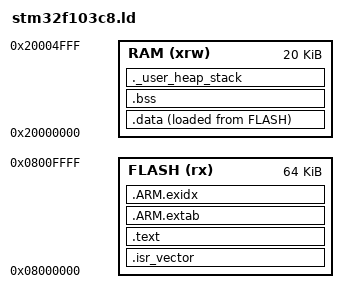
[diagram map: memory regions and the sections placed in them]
/* STM32F103C8: 64 KiB flash, 20 KiB SRAM. */
ENTRY(Reset_Handler)

MEMORY
{
    FLASH (rx)  : ORIGIN = 0x08000000, LENGTH = 64K
    RAM   (xrw) : ORIGIN = 0x20000000, LENGTH = 20K
}

_estack = ORIGIN(RAM) + LENGTH(RAM);
_Min_Heap_Size = 0x000;
_Min_Stack_Size = 0x600;

SECTIONS
{
    .isr_vector :
    {
        . = ALIGN(4);
        KEEP(*(.isr_vector))
        . = ALIGN(4);
    } > FLASH

    .text :
    {
        . = ALIGN(4);
        *(.text)
        *(.text*)
        *(.rodata)
        *(.rodata*)
        KEEP(*(.init))
        KEEP(*(.fini))
        . = ALIGN(4);
        _etext = .;
    } > FLASH

    .ARM.extab :
    {
        *(.ARM.extab* .gnu.linkonce.armextab.*)
    } > FLASH

    .ARM.exidx :
    {
        __exidx_start = .;
        *(.ARM.exidx*)
        __exidx_end = .;
    } > FLASH

    _sidata = LOADADDR(.data);

    .data :
    {
        . = ALIGN(4);
        _sdata = .;
        *(.data)
        *(.data*)
        . = ALIGN(4);
        _edata = .;
    } > RAM AT > FLASH

    .bss (NOLOAD) :
    {
        . = ALIGN(4);
        _sbss = .;
        *(.bss)
        *(.bss*)
        *(COMMON)
        . = ALIGN(4);
        _ebss = .;
    } > RAM

    ._user_heap_stack (NOLOAD) :
    {
        . = ALIGN(8);
        PROVIDE(end = .);
        PROVIDE(_end = .);
        . = . + _Min_Heap_Size;
        . = . + _Min_Stack_Size;
        . = ALIGN(8);
    } > RAM

    /DISCARD/ :
    {
        *(.note.GNU-stack)
        *(.comment)
    }
}
